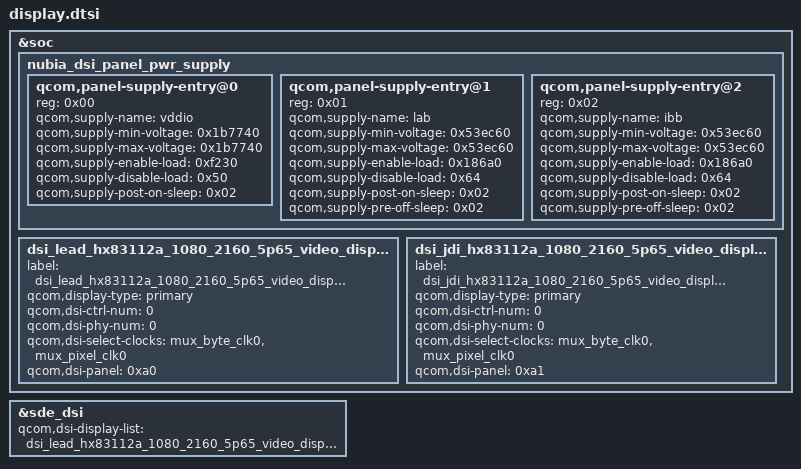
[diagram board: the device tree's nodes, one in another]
&soc {
	nubia_dsi_panel_pwr_supply: nubia_dsi_panel_pwr_supply {
			#address-cells = <0x01>;
			#size-cells = <0x00>;
			
			qcom,panel-supply-entry@0 {
				reg = <0x00>;
				qcom,supply-name = "vddio";
				qcom,supply-min-voltage = <0x1b7740>;
				qcom,supply-max-voltage = <0x1b7740>;
				qcom,supply-enable-load = <0xf230>;
				qcom,supply-disable-load = <0x50>;
				qcom,supply-post-on-sleep = <0x02>;
			};

			qcom,panel-supply-entry@1 {
				reg = <0x01>;
				qcom,supply-name = "lab";
				qcom,supply-min-voltage = <0x53ec60>;
				qcom,supply-max-voltage = <0x53ec60>;
				qcom,supply-enable-load = <0x186a0>;
				qcom,supply-disable-load = <0x64>;
				qcom,supply-post-on-sleep = <0x02>;
				qcom,supply-pre-off-sleep = <0x02>;
			};

			qcom,panel-supply-entry@2 {
				reg = <0x02>;
				qcom,supply-name = "ibb";
				qcom,supply-min-voltage = <0x53ec60>;
				qcom,supply-max-voltage = <0x53ec60>;
				qcom,supply-enable-load = <0x186a0>;
				qcom,supply-disable-load = <0x64>;
				qcom,supply-post-on-sleep = <0x02>;
				qcom,supply-pre-off-sleep = <0x02>;
			};
	};

			dsi_lead_hx83112a_1080_2160_5p65_video_display: qcom,dsi-display@23 {
				label = "dsi_lead_hx83112a_1080_2160_5p65_video_display";
				qcom,display-type = "primary";
				qcom,dsi-ctrl-num = <0>;
				qcom,dsi-phy-num = <0>;
				qcom,dsi-select-clocks = "mux_byte_clk0", "mux_pixel_clk0";
				qcom,dsi-panel = <0xa0>;
			};
			dsi_jdi_hx83112a_1080_2160_5p65_video_display: qcom,dsi-display@24 {
				label = "dsi_jdi_hx83112a_1080_2160_5p65_video_display";
				qcom,display-type = "primary";
				qcom,dsi-ctrl-num = <0>;
				qcom,dsi-phy-num = <0>;
				qcom,dsi-select-clocks = "mux_byte_clk0", "mux_pixel_clk0";
				qcom,dsi-panel = <0xa1>;
			};
};

&sde_dsi{
		qcom,dsi-display-list =
			<&dsi_lead_hx83112a_1080_2160_5p65_video_display
			dsi_jdi_hx83112a_1080_2160_5p65_video_display>;
};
